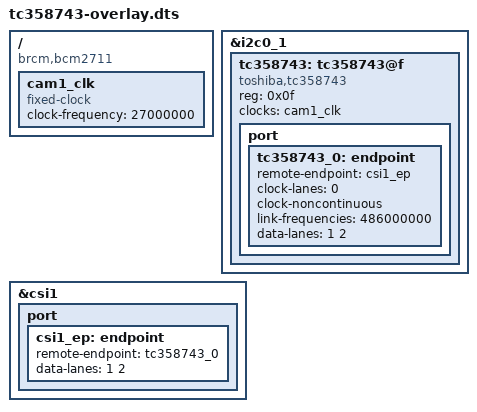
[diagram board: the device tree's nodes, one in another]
/dts-v1/;
/plugin/;

/ {
  compatible = "brcm,bcm2711";
  fragment@0 {
    target-path = "/";
    __overlay__ {
      cam1_clk: cam1_clk {
        compatible = "fixed-clock";
        #clock-cells = <0>;
        status = "okay";
        clock-frequency = <27000000>;
      };
    };
  };
  fragment@1 {
    target = <&i2c0_1>;
    __overlay__ {
      #address-cells = <1>;
      #size-cells = <0>;
      status = "okay";

      tc358743: tc358743@f {
        compatible = "toshiba,tc358743";
        reg = <0x0f>;
        status = "okay";

        clocks = <&cam1_clk>;
        clock-names = "refclk";

        port {
          tc358743_0: endpoint {
            remote-endpoint = <&csi1_ep>;
            clock-lanes = <0>;
            clock-noncontinuous;
            link-frequencies = /bits/ 64 <486000000>;
            data-lanes = <1 2>;
          };
        };
      };
    };
  };
  fragment@2 {
    target = <&csi1>;
    __overlay__ {
      status = "okay";
      port {
        csi1_ep: endpoint {
          remote-endpoint = <&tc358743_0>;
          data-lanes = <1 2>;
        };
      };
    };
  };
};

